VERSION "2010_Scion_xB_automatic"

NS_ :

    ENVVAR DATA
    SGTYPE_
    SGTYPE_VAL_
    BA_DEF_SGTYPE_
    BA_SGTYPE_
    SIG_TYPE_REF_
    VAL_TABLE_
    SIG_GROUP_
    SIG_VALTYPE_
    SIGTYPE_VALTYPE
    BO_TX_BU_
    BA_DEF_REL_
    BA_REL_
    BA_DEF_DEF_REL_
    BU_SG_REL_
    BU_EV_REL_
    BU_BO_REL
    SG_MUL_VAL_

BS_:

BU_: HSCAN

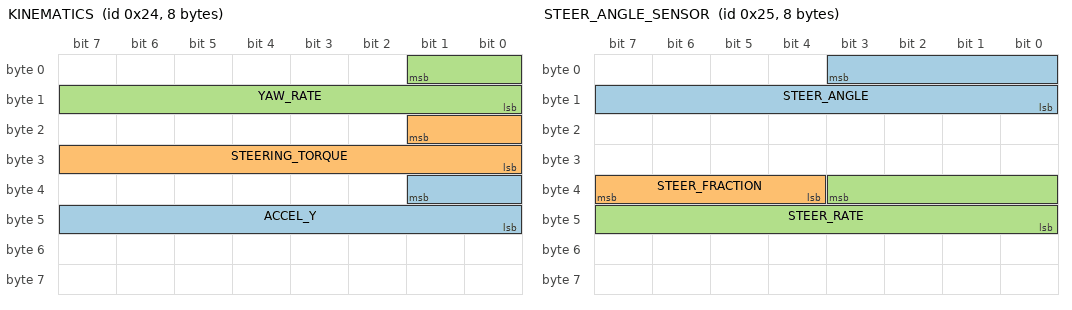
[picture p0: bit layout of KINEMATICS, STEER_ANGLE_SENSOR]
BO_ 36 KINEMATICS: 8 HSCAN
 SG_ ACCEL_Y: 33|10@0+ (1,-512) [0|65535] "" HSCAN
 SG_ STEERING_TORQUE : 17|10@0+ (1,-512) [0|65535] "" HSCAN
 SG_ YAW_RATE : 1|10@0+ (1,-512) [0|65535] "" HSCAN

BO_ 37 STEER_ANGLE_SENSOR: 8 HSCAN
 SG_ STEER_ANGLE: 3|12@0- (1.5,0) [-500|500] "deg" HSCAN
 SG_ STEER_FRACTION : 39|4@0- (0.1,0) [-0.7| 0.7] "deg" HSCAN
 SG_ STEER_RATE : 35|12@0- (1,0) [-2000|2000] "deg/s" HSCAN

BO_ 176 WHEEL_SPEED_1: 8 HSCAN
 SG_ WHEEL_SPEED_FL : 7|16@0+ (0.0125,0) [0|655.35] "kph" HSCAN
 SG_ WHEEL_SPEED_FR: 23|16@0+ (0.0125,0) [0|655.35] "kph" HSCAN

BO_ 178 WHEEL_SPEED_2: 8 HSCAN
 SG_ WHEEL_SPEED_RL : 7|16@0+ (0.0125,0) [0|655.35] "kph" HSCAN
 SG_ WHEEL_SPEED_RR: 23|16@0+ (0.0125,0) [0|655.35] "kph" HSCAN

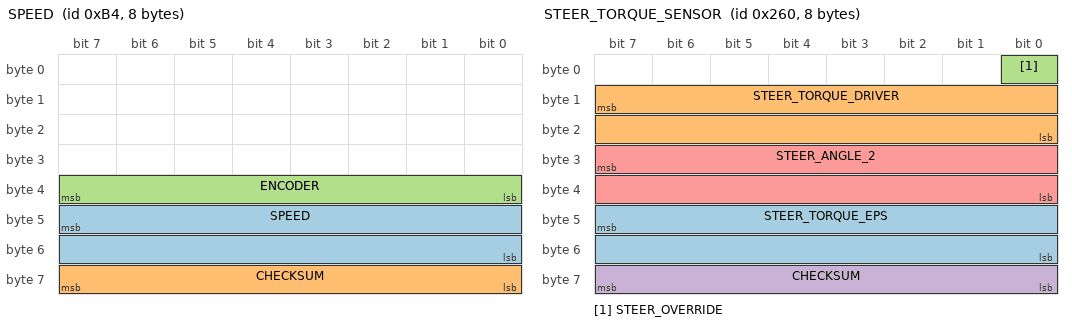
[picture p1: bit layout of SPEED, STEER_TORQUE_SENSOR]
BO_ 180 SPEED: 8 HSCAN
 SG_ SPEED : 47|16@0+ (0.0062,0) [0|115] "mph" HSCAN
 SG_ CHECKSUM: 63|8@0+ (1,0) [0|255] "" HSCAN
 SG_ ENCODER: 39|8@0+ (1,0) [0|255] "" HSCAN

BO_ 548 BRAKE_DATA: 8 HSCAN
 SG_ Brake_Switch : 5|1@1+ (1,0) [0|1] "" HSCAN
 SG_ Brake_Pressure: 40|8@1+ (1,0) [0|255] "" HSCAN

BO_ 608 STEER_TORQUE_SENSOR: 8 HSCAN
 SG_ STEER_TORQUE_EPS : 47|16@0- (0.73,0) [-20000|20000] "" HSCAN
 SG_ STEER_TORQUE_DRIVER: 15|16@0- (1,0) [-32768|32767] "" HSCAN
 SG_ STEER_OVERRIDE : 0|1@0+ (1,0) [0|1] "" HSCAN
 SG_ CHECKSUM : 63|8@0+ (1,0) [0|255] "" HSCAN
 SG_ STEER_ANGLE_2:31|16@0- (0.0573,0) [-500|500] "" HSCAN

BO_ 708 ENGINE_DATA: 8 HSCAN
 SG_ RPM: 7|16@0- (0.78125,0) [0|0] "rpm" HSCAN
 SG_ CHECKSUM: 63|8@0+ (1,0) [0|255] "" HSCAN

BO_ 947 LOW_RES_INDICATORS: 8 HSCAN
 SG_ LOW_RES_ACC_PEDAL: 23|7@0+ (1,0) [0|63] "" HSCAN
 SG_ LOW_RES_RPM: 7|16@0+ (0.78125,0) [0|0] "rpm" HSCAN

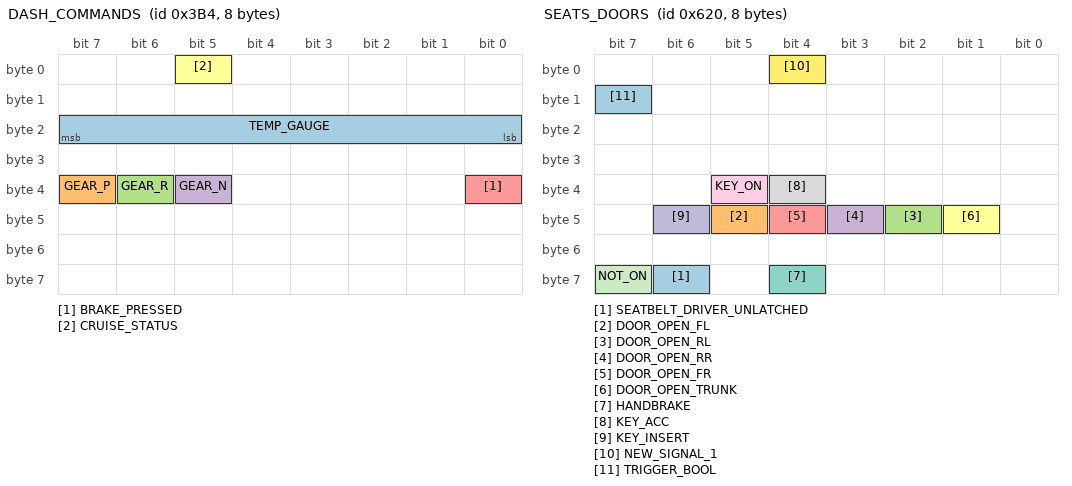
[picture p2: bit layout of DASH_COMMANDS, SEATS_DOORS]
BO_ 948 DASH_COMMANDS: 8 HSCAN
 SG_ TEMP_GAUGE: 16|8@1+ (1,0) [0|255] "degF" HSCAN
 SG_ GEAR_P: 39|1@1+ (1,0) [0|1] "" HSCAN
 SG_ GEAR_R: 38|1@1+ (1,0) [0|1] "" HSCAN
 SG_ GEAR_N: 37|1@1+ (1,0) [0|1] "" HSCAN
 SG_ BRAKE_PRESSED: 32|1@1+ (1,0) [0|1] "" HSCAN
 SG_ CRUISE_STATUS: 5|1@1+ (1,0) [0|1] "" HSCAN

BO_ 951 VSC_STATUS: 8 ESP
 SG_ VSC_OFF_BIT: 12|1@0+ (1,0) [0|1] "" HSCAN
 SG_ TC_OFF_BIT: 11|1@0+ (1,0) [0|1] "" HSCAN

BO_ 1552 DASH_DISPLAY_FEED: 8 HSCAN
 SG_ INSTANT_ECONOMY : 16|8@1+ (1,0) [0|255] "Unit" HSCAN

BO_ 1553 UI_SETTING: 8 HSCAN
 SG_ UNITS: 26|2@0+ (1,0) [0|3] "" HSCAN
 SG_ ODOMETER: 43|20@0+ (1,0) [0|1048575] "" HSCAN
 SG_ TOTAL_DISTANCE: 55|16@0+ (1,0) [0|65535] "" HSCAN

BO_ 1568 SEATS_DOORS: 8 HSCAN
 SG_ SEATBELT_DRIVER_UNLATCHED : 62|1@0+ (1,0) [0|1] "" HSCAN
 SG_ DOOR_OPEN_FL: 45|1@0+ (1,0) [0|1] "" HSCAN
 SG_ DOOR_OPEN_RL: 42|1@0+ (1,0) [0|1] "" HSCAN
 SG_ DOOR_OPEN_RR: 43|1@0+ (1,0) [0|1] "" HSCAN
 SG_ DOOR_OPEN_FR: 44|1@0+  (1,0) [0|1] "" HSCAN
 SG_ DOOR_OPEN_TRUNK: 41|1@1+ (1,0) [0|3] "" HSCAN
 SG_ HANDBRAKE: 60|1@0+ (1,0) [0|3] "" HSCAN
 SG_ KEY_ACC: 36|1@0+ (1,0) [0|1] "" HSCAN
 SG_ KEY_ON: 37|1@0+ (1,0) [0|1] "" HSCAN
 SG_ KEY_INSERT: 46|1@0+ (1,0) [0|1] "" HSCAN
 SG_ NOT_ON: 63|1@0+ (1,0) [0|1] "" HSCAN
 SG_ NEW_SIGNAL_1: 4|1@0+ (1,0) [0|1] "" HSCAN
 SG_ TRIGGER_BOOL: 15|1@0+ (1,0) [0|1] "" HSCAN

BO_ 1569 DOOR_LOCK_REQUEST: 8 HSCAN
 SG_ LOCK_CMD: 0|8@0+ (1,0) [0|255] "" HSCAN

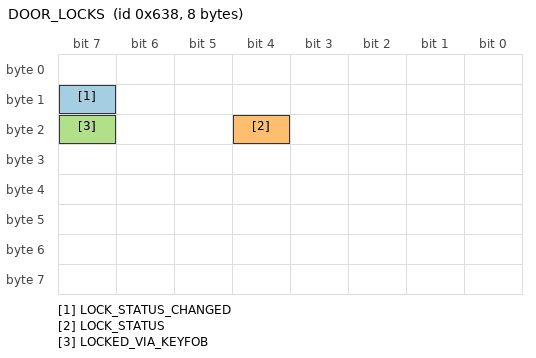
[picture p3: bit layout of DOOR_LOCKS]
BO_ 1592 DOOR_LOCKS: 8 HSCAN
 SG_ LOCK_STATUS_CHANGED: 15|1@0+ (1,0) [0|1] "" HSCAN
 SG_ LOCK_STATUS: 20|1@0+ (1,0) [0|1] "" HSCAN
 SG_ LOCKED_VIA_KEYFOB: 23|1@0+ (1,0) [0|1] "" HSCAN

BA_DEF_ BO_ "GenMsgBackgroundColor" STRING;
BA_DEF_ BO_ "GenMsgForegroundColor" STRING;
BA_DEF_ BO_ "labelfilters" INT 0 0;
BA_DEF_DEF_ "GenMsgBackgroundColor" "#ffffff";
BA_DEF_DEF_ "GenMsgForegroundColor" "#000000";
BA_DEF_DEF_ "labelfilters" 1;
VAL_ 951 VSC_OFF_BIT 1 "Disabled" 0 "Enabled" ;
VAL_ 948 CRUISE_STATUS 1 "Cruise ON" 0 "Cruise OFF" ;
VAL_ 948 BRAKE_PRESSED 1 "Brake Pressed" 0 "Brake Released" ;
VAL_ 1553 UNITS 1 "km" 2 "miles";
